VERSION ""

NS_ :

BS_: 500

BU_: Vector__XXX

BO_ 258 MSG_102: 8 Vector__XXX
 SG_ Steering_Rate : 32|14@0+ (0.5,-2048) [-2048|2047] "" Vector__XXX
 SG_ Steering_Angle : 48|16@0+ (-0.5,2048) [-540|540] "��" Vector__XXX

BO_ 264 MSG_108: 8 Vector__XXX
 SG_ Engine_Speed : 48|16@0+ (1,0) [0|10000] "rpm" Vector__XXX

BO_ 284 MSG_11C: 8 Vector__XXX
 SG_ Indicated_Vehicle_Speed : 16|16@0+ (0.0078125,0) [0|511.984375] "" Vector__XXX
 SG_ Brake_Position : 48|16@0+ (0.0244,0) [0|100] "%" Vector__XXX

BO_ 288 MSG_120: 8 Vector__XXX
 SG_ Accelerator_Pedal_Position : 40|8@0+ (0.4,0) [0|100] "%" Vector__XXX

BO_ 324 MSG_144: 8 Vector__XXX
 SG_ Gear : 48|4@0+ (1,0) [0|15] "" Vector__XXX
 SG_ Gear_Requested : 52|4@0+ (1,0) [0|15] "" Vector__XXX

BO_ 344 MSG_158: 8 Vector__XXX
 SG_ Wheel_Speed_RR_kph : 0|14@0+ (0.068264,0) [0|644] "km/h" Vector__XXX
 SG_ Wheel_Speed_RR_mph : 0|14@0+ (0.0424,0) [0|400] "mph" Vector__XXX
 SG_ Wheel_Speed_RL_kph : 16|14@0+ (0.06762,0) [0|644] "km/h" Vector__XXX
 SG_ Wheel_Speed_RL_mph : 16|14@0+ (0.042,0) [0|400] "mph" Vector__XXX
 SG_ Wheel_Speed_FR_kph : 32|14@0+ (0.06762,0) [0|644] "km/h" Vector__XXX
 SG_ Wheel_Speed_FR_mph : 32|14@0+ (0.042,0) [0|400] "mph" Vector__XXX
 SG_ Wheel_Speed_FL_kph : 48|14@0+ (0.06762,0) [0|644] "km/h" Vector__XXX
 SG_ Wheel_Speed_FL_mph : 48|14@0+ (0.042,0) [0|400] "mph" Vector__XXX

BO_ 384 MSG_180: 8 Vector__XXX
 SG_ Air_Temperature : 0|8@1+ (1,-40) [-40|214] "��C" Vector__XXX
 SG_ Coolant_Temperature : 8|8@1+ (1,-40) [-40|214] "��C" Vector__XXX

BO_ 512 MSG_200: 8 Vector__XXX
 SG_ Battery_Voltage : 48|8@1+ (0.1,0) [5|18] "V" Vector__XXX

BO_ 584 MSG_248: 8 Vector__XXX
 SG_ Door_Open___Front_Left : 0|1@1+ (1,0) [0|0] "" Vector__XXX
 SG_ Door_Open___Front_Right : 1|1@1+ (1,0) [0|0] "" Vector__XXX

BO_ 672 MSG_2A0: 8 Vector__XXX
 SG_ Oil_Pressure : 16|8@1+ (4,0) [0|1016] "kPaG" Vector__XXX
 SG_ Oil_Temperature : 24|8@1+ (1,-40) [-40|160] "��C" Vector__XXX

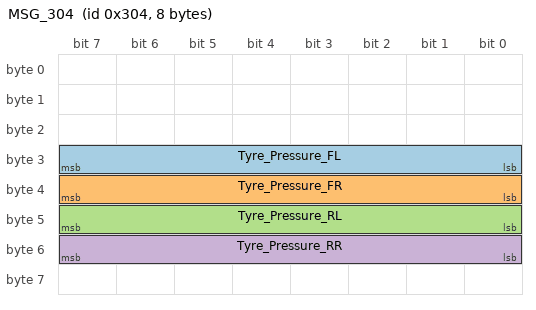
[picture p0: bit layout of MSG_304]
BO_ 772 MSG_304: 8 Vector__XXX
 SG_ Tyre_Pressure_FL : 24|8@1+ (1,0) [0|126] "psi" Vector__XXX
 SG_ Tyre_Pressure_FR : 32|8@1+ (1,0) [0|126] "psi" Vector__XXX
 SG_ Tyre_Pressure_RL : 40|8@1+ (1,0) [0|126] "psi" Vector__XXX
 SG_ Tyre_Pressure_RR : 48|8@1+ (1,0) [0|126] "psi" Vector__XXX
